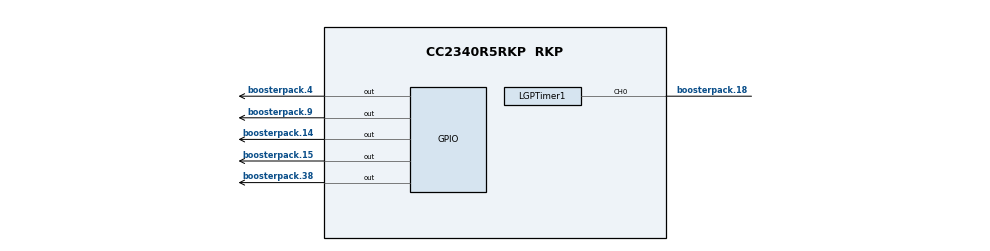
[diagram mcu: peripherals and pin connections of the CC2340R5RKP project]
/**
 * @cliArgs --board "/ti/boards/LP_EM_CC2340R5" --device "CC2340R5RKP" --part "Default" --package "RKP" --rtos "freertos" --product "simplelink_lowpower_f3_sdk@9.20.00.81"
 * @versions {"tool":"1.26.3+4558"}
 */

/**
 * Import the modules used in this configuration.
 */
const FreeRTOS  = scripting.addModule("/freertos/FreeRTOS");
const ble       = scripting.addModule("/ti/ble/ble");
const CCFG      = scripting.addModule("/ti/devices/CCFG");
const rfdesign  = scripting.addModule("/ti/devices/radioconfig/rfdesign");
const GPIO      = scripting.addModule("/ti/drivers/GPIO");
const GPIO1     = GPIO.addInstance();
const GPIO2     = GPIO.addInstance();
const GPIO3     = GPIO.addInstance();
const GPIO4     = GPIO.addInstance();
const GPIO5     = GPIO.addInstance();
const GPIO6     = GPIO.addInstance();
const GPIO7     = GPIO.addInstance();
const LGPTimer  = scripting.addModule("/ti/drivers/LGPTimer", {}, false);
const LGPTimer1 = LGPTimer.addInstance();
const LGPTimer2 = LGPTimer.addInstance();
const NVS       = scripting.addModule("/ti/drivers/NVS");
const NVS1      = NVS.addInstance();
const Power     = scripting.addModule("/ti/drivers/Power");
const RCL       = scripting.addModule("/ti/drivers/RCL");
const RNG       = scripting.addModule("/ti/drivers/RNG");
const Settings  = scripting.addModule("/ti/posix/freertos/Settings");

/**
 * Write custom configuration values to the imported modules.
 */
FreeRTOS.heapSize       = 0x00004D50;
FreeRTOS.timerStackSize = 0x00000190;
FreeRTOS.idleStackSize  = 0x00000130;

ble.basicBLE                                        = true;
ble.disDevBySerUuid                                 = true;
ble.numOfAdvSets                                    = 1;
ble.addressMode                                     = "ADDRMODE_PUBLIC";
ble.bondPairing                                     = "GAPBOND_PAIRING_MODE_NO_PAIRING";
ble.bonding                                         = false;
ble.bondMITMProtection                              = false;
ble.allowDebugKeys                                  = false;
ble.bondManager                                     = false;
ble.deviceName                                      = "";
ble.disableDisplayModule                            = true;
ble.paramUpdateReq                                  = "GAP_UPDATE_REQ_ACCEPT_ALL";
ble.L2CAPCOC                                        = true;
ble.persistentStorage                               = false;
ble.sendParamsUpdateReq                             = false;
ble.radioConfig.codeExportConfig.$name              = "ti_devices_radioconfig_code_export_param0";
ble.adcNoiseConfig.codeExportConfig.$name           = "ti_devices_radioconfig_code_export_param1";
ble.bleCsConfig.codeExportConfig.$name              = "ti_devices_radioconfig_code_export_param2";
ble.advSet1.$name                                   = "ti_ble_broadcaster_advertisement_set0";
ble.advSet1.advParam1.$name                         = "ti_ble_broadcaster_advertisement_params0";
ble.advSet1.advParam1.primIntMin                    = 2000;
ble.advSet1.advParam1.primIntMax                    = 2000;
ble.advSet1.advData1.$name                          = "ti_ble_broadcaster_advertisement_data0";
ble.advSet1.advData1.numOfUUIDs16More               = 1;
ble.advSet1.advData1.numOfUUIDs128More              = 1;
ble.advSet1.advData1.advIntValue                    = 210;
ble.advSet1.advData1.GAP_ADTYPE_ADV_INTERVAL        = true;
ble.advSet1.scanRes1.$name                          = "ti_ble_broadcaster_advertisement_data1";
ble.advSet1.scanRes1.numOfUUIDs128More              = 1;
ble.advSet1.scanRes1.UUID0128More                   = system.utils.bigInt("FFF000001000800000805F9B34FB",16);
ble.advSet1.scanRes1.GAP_ADTYPE_LOCAL_NAME_COMPLETE = false;
ble.advSet1.scanRes1.GAP_ADTYPE_POWER_LEVEL         = false;
ble.advSet1.scanRes1.advIntValue                    = 210;
ble.advSet1.scanRes1.companyIdentifier              = 0x0000;
ble.rng.$name                                       = "CONFIG_RNG_0";
ble.aesccm.$name                                    = "CONFIG_AESCCM_0";
ble.ecdh.$name                                      = "CONFIG_ECDH_0";
ble.aesctrdrbg.$name                                = "CONFIG_AESCTRDRBG_0";
ble.aesecb.$name                                    = "CONFIG_AESECB_0";

CCFG.srcClkLF           = "LF RCOSC";
CCFG.ccfgTemplate.$name = "ti_devices_CCFG_CCFGCC23X0Template0";

GPIO1.$name           = "CONFIG_GPIO_DC2DC_ENA";
GPIO1.pull            = "Pull Up";
GPIO1.mode            = "Output";
GPIO1.gpioPin.$assign = "boosterpack.14";
scripting.suppress("Connected to hardware,@@@.+?@@@ is connected to LaunchPad SPI Bus on the CC2340R5 Development Platform\\. Consider selecting it in \'use hardware\' above\\. @@@.+?@@@", GPIO1, "gpioPin");

GPIO2.$name = "CONFIG_GPIO_DIO8";

GPIO3.$name           = "CONFIG_GPIO_DIO13";
GPIO3.pull            = "Pull Up";
GPIO3.gpioPin.$assign = "boosterpack.15";
scripting.suppress("Connected to hardware,@@@.+?@@@ is connected to LaunchPad SPI Bus on the CC2340R5 Development Platform\\. Consider selecting it in \'use hardware\' above\\. @@@.+?@@@", GPIO3, "gpioPin");

GPIO4.$name           = "CONFIG_GPIO_DIO20";
GPIO4.pull            = "Pull Up";
GPIO4.gpioPin.$assign = "boosterpack.4";
scripting.suppress("Connected to hardware,@@@.+?@@@ is connected to XDS110 UART on the CC2340R5 Development Platform\\. Consider selecting it in \'use hardware\' above\\. @@@.+?@@@", GPIO4, "gpioPin");

GPIO5.$name = "CONFIG_GPIO_DIO21";
GPIO5.pull  = "Pull Up";

GPIO6.$name           = "CONFIG_GPIO_DIO24";
GPIO6.pull            = "Pull Up";
GPIO6.gpioPin.$assign = "boosterpack.9";

GPIO7.$name           = "CONFIG_GPIO_DIO06";
GPIO7.pull            = "Pull Up";
GPIO7.gpioPin.$assign = "boosterpack.38";
scripting.suppress("Connected to hardware,@@@.+?@@@ is connected to MX25R8035F SPI Flash Chip Select on the CC2340R5 Development Platform\\. Consider selecting it in \'use hardware\' above\\. @@@.+?@@@", GPIO7, "gpioPin");

LGPTimer1.$name                = "CONFIG_LGPTIMER_0";
LGPTimer1.channel0Connection   = "Pin";
LGPTimer1.timer.$assign        = "LGPT0";
LGPTimer1.timer.ch0Pin.$assign = "boosterpack.18";
scripting.suppress("Connected to hardware,@@@.+?@@@ is connected to LaunchPad SPI Bus Chip Select on the CC2340R5 Development Platform\\. Consider selecting it in \'use hardware\' above\\. @@@.+?@@@", LGPTimer1.timer, "ch0Pin");

LGPTimer2.$name         = "CONFIG_LGPTIMER_1";
LGPTimer2.timer.$assign = "LGPT1";

NVS1.$name                    = "CONFIG_NVSINTERNAL";
NVS1.internalFlash.$name      = "ti_drivers_nvs_NVSLPF30";
NVS1.internalFlash.regionBase = 0x7D000;
NVS1.internalFlash.regionSize = 0x3000;

RNG.rngReturnBehavior = "RNG_RETURN_BEHAVIOR_BLOCKING";

const AESCommonXXF3 = scripting.addModule("/ti/drivers/cryptoutils/aes/AESCommonXXF3", {}, false);

/**
 * Pinmux solution for unlocked pins/peripherals. This ensures that minor changes to the automatic solver in a future
 * version of the tool will not impact the pinmux you originally saw.  These lines can be completely deleted in order to
 * re-solve from scratch.
 */
GPIO2.gpioPin.$suggestSolution                       = "boosterpack.36";
GPIO5.gpioPin.$suggestSolution                       = "boosterpack.17";
AESCommonXXF3.laes.$suggestSolution                  = "LAES";
AESCommonXXF3.laes.dataLaesChannelA.$suggestSolution = "DMA_CH4";
AESCommonXXF3.laes.dataLaesChannelB.$suggestSolution = "DMA_CH5";
